# PIC32MK1024MCF064 register map
Vendor: Microchip
Registers are 32-bit, read-write, reset 0x0 unless marked. A register's access mark holds for its fields unless they carry their own. Addresses are absolute, and some are shared; only a register's first bit layout is shown; [hi:lo] are bit positions; {n}, {i} and the like mark numbered series.

## CFG
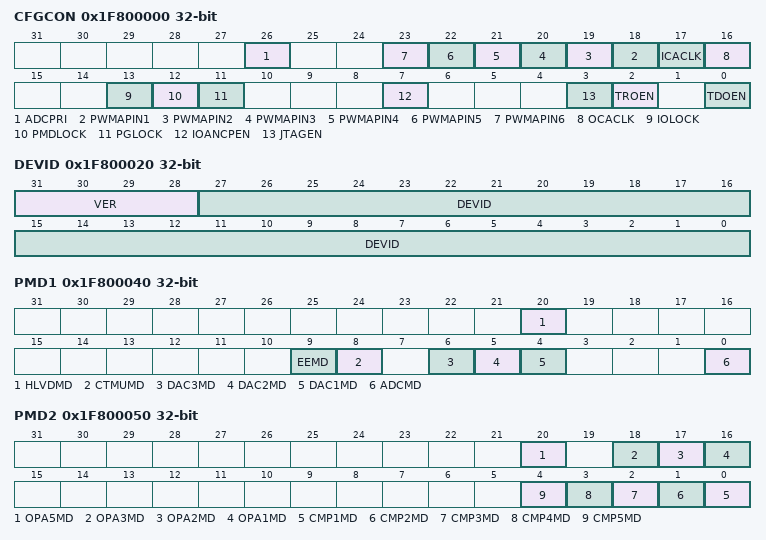
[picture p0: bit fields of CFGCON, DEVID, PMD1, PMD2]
0x1F800000 CFGCON reset not defined — (power-on value -----0--xxxxxx00--000---0---10-1)
  [26] ADCPRI, [n+17] PWMAPIN{n} (n=1..6), [17] ICACLK, [16] OCACLK, [13] IOLOCK, [12] PMDLOCK, [11] PGLOCK, [7] IOANCPEN, [3] JTAGEN, [2] TROEN, [0] TDOEN
0x1F800020 DEVID reset not defined — (power-on value 0000xxxxxxxxxxxxxxxxxxxxxxxxxxxx)
  [31:28] VER ro, [27:0] DEVID
0x1F800030 SYSKEY
0x1F800040 PMD1 reset not defined — (power-on value -----------x---------xxx-xxx---0)
  [20] HLVDMD, [9] EEMD, [8] CTMUMD, [6] DAC3MD, [5] DAC2MD, [4] DAC1MD, [0] ADCMD
0x1F800050 PMD2 reset not defined — (power-on value -----------x-xxx-----------xxx00)
  [20] OPA5MD, [18] OPA3MD, [17] OPA2MD, [16] OPA1MD, [n-1] CMP{n}MD (n=1..5)
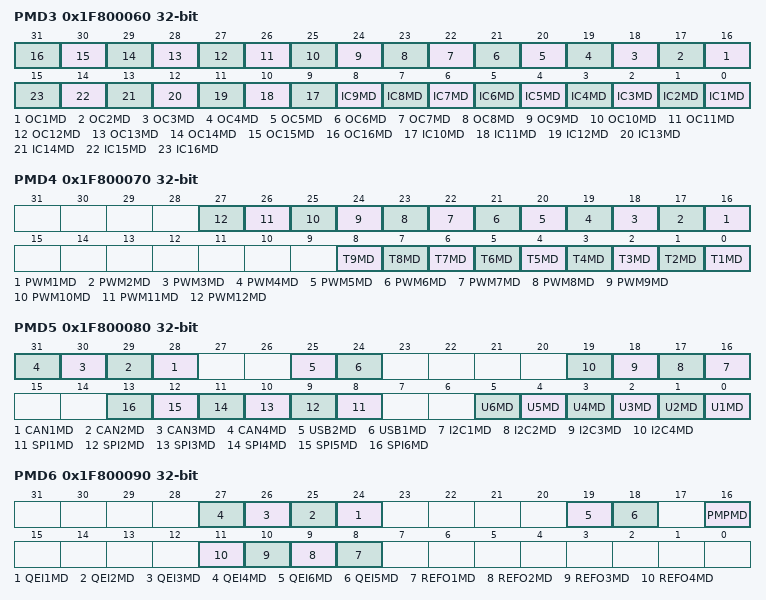
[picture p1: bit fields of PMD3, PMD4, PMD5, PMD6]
0x1F800060 PMD3 reset not defined — (power-on value xxxxxxx000000000xxxxxxx000000000)
  [n+15] OC{n}MD (n=1..16), [n-1] IC{n}MD (n=1..16)
0x1F800070 PMD4 reset not defined — (power-on value ----xxxxxxxxxxxx-------111111111)
  [n+15] PWM{n}MD (n=1..12), [n-1] T{n}MD (n=1..9)
0x1F800080 PMD5 reset not defined — (power-on value xx00--x0----0000--000000--000000)
  [n+27] CAN{n}MD (n=1..4), [25] USB2MD, [24] USB1MD, [n+15] I2C{n}MD (n=1..4), [n+7] SPI{n}MD (n=1..6), [n-1] U{n}MD (n=1..6)
0x1F800090 PMD6 reset not defined — (power-on value ----xxxx----xxx0----0000--------)
  [n+23] QEI{n}MD (n=1..4), [19] QEI6MD, [18] QEI5MD, [16] PMPMD, [n+7] REFO{n}MD (n=1..4)
0x1F8000A0 PMD7
  [4] DMAMD
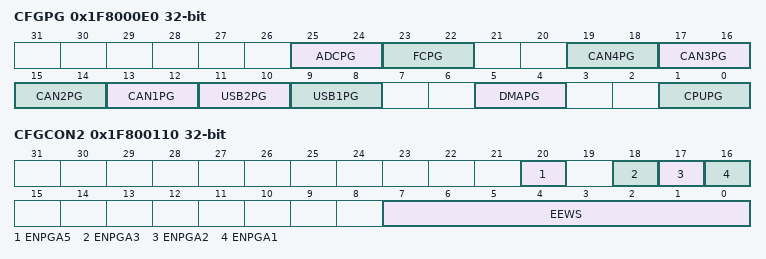
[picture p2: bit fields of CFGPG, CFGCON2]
0x1F8000E0 CFGPG reset not defined — (power-on value ------0000--00000000xx00--00--00)
  [25:24] ADCPG, [23:22] FCPG, [2n+11:2n+10] CAN{n}PG (n=1..4), [11:10] USB2PG, [9:8] USB1PG, [5:4] DMAPG, [1:0] CPUPG
0x1F800110 CFGCON2 reset not defined — (power-on value -----------x-xxx--------00000000)
  [20] ENPGA5, [18] ENPGA3, [17] ENPGA2, [16] ENPGA1, [7:0] EEWS

## PCACHE
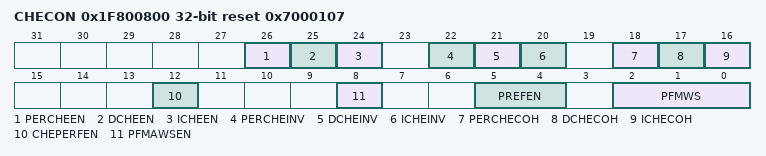
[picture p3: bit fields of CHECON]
0x1F800800 CHECON reset 0x7000107
  [26] PERCHEEN, [25] DCHEEN, [24] ICHEEN, [22] PERCHEINV, [21] DCHEINV, [20] ICHEINV, [18] PERCHECOH, [17] DCHECOH, [16] ICHECOH, [12] CHEPERFEN, [8] PFMAWSEN, [5:4] PREFEN, [2:0] PFMWS
0x1F800820 CHEHIT reset not defined — (power-on value xxxxxxxxxxxxxxxxxxxxxxxxxxxxxxxx)
  [31:0] CHEHIT — (can only be cleared)
0x1F800830 CHEMIS reset not defined — (power-on value xxxxxxxxxxxxxxxxxxxxxxxxxxxxxxxx)
  [31:0] CHEMIS — (can only be cleared)

## NVM
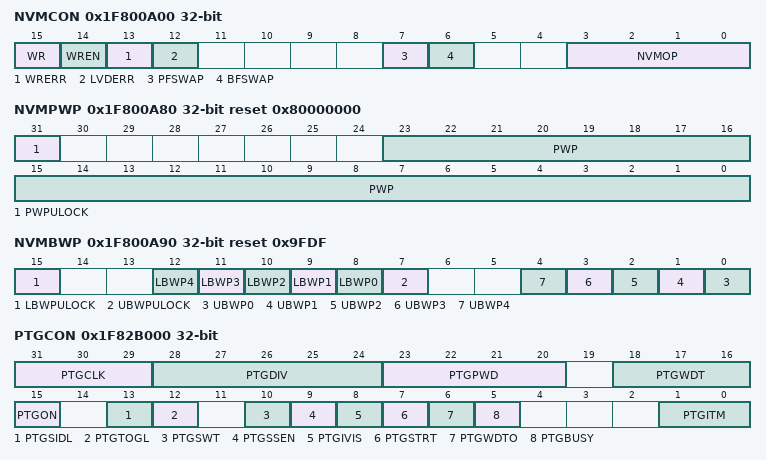
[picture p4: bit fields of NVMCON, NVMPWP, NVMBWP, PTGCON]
0x1F800A00 NVMCON reset not defined — (power-on value ----------------0000----0x--0000)
  [15] WR, [14] WREN, [13] WRERR, [12] LVDERR, [7] PFSWAP, [6] BFSWAP, [3:0] NVMOP
0x1F800A10 NVMKEY wo
0x1F800A20 NVMADDR
{0x1F800A30+0x10*i} NVMDATA{i} (i=0..3)
0x1F800A70 NVMSRCADDR
0x1F800A80 NVMPWP reset 0x80000000
  [31] PWPULOCK, [23:0] PWP
0x1F800A90 NVMBWP reset 0x9FDF
  [15] LBWPULOCK, [n+8] LBWP{n} (n=0..4), [7] UBWPULOCK, [n] UBWP{n} (n=0..4)
0x1F800AA0 NVMCON2 reset not defined — (power-on value xxxx-------xxxxxx-xx--xx00------)
  [7:6] SWAPLOCK
0x1F82B000 PTGCON
  [31:29] PTGCLK, [28:24] PTGDIV, [23:20] PTGPWD, [18:16] PTGWDT, [15] PTGON, [13] PTGSIDL, [12] PTGTOGL, [10] PTGSWT, [9] PTGSSEN, [8] PTGIVIS, [7] PTGSTRT, [6] PTGWDTO ro, [5] PTGBUSY ro, [1:0] PTGITM
0x1F82B010 PTGBTE
0x1F82B020 PTGHOLD
  [15:0] PTGHOLD
0x1F82B030 PTGT0LIM
  [15:0] PTGT0LIM
0x1F82B040 PTGT1LIM
  [15:0] PTGT1LIM
0x1F82B050 PTGSDLIM
  [15:0] PTGSDLIM
0x1F82B060 PTGC0LIM
  [15:0] PTGC0LIM
0x1F82B070 PTGC1LIM
  [15:0] PTGC1LIM
0x1F82B080 PTGADJ
  [15:0] PTGADJ
0x1F82B090 PTGL0
  [15:0] PTGL0
0x1F82B0A0 PTGQPTR
  [4:0] PTGQPTR
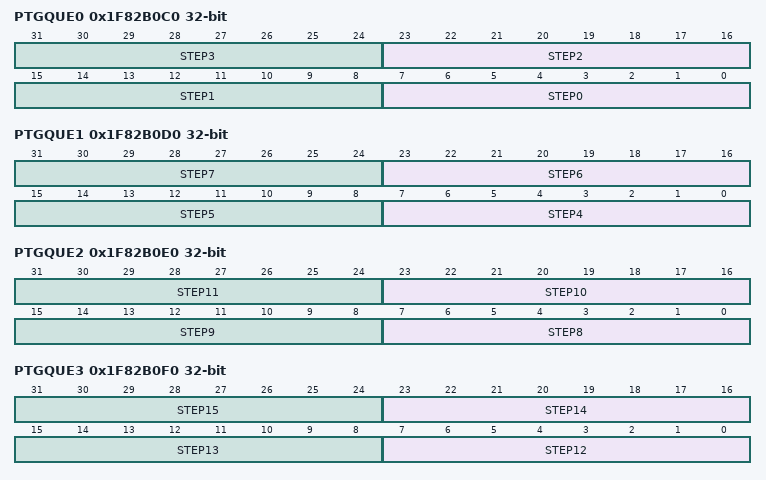
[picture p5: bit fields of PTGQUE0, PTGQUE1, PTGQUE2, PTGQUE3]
0x1F82B0C0 PTGQUE0
  [8n+7:8n] STEP{n} (n=0..3)
0x1F82B0D0 PTGQUE1
  [8n-25:8n-32] STEP{n} (n=4..7)
0x1F82B0E0 PTGQUE2
  [8n-57:8n-64] STEP{n} (n=8..11)
0x1F82B0F0 PTGQUE3
  [8n-89:8n-96] STEP{n} (n=12..15)
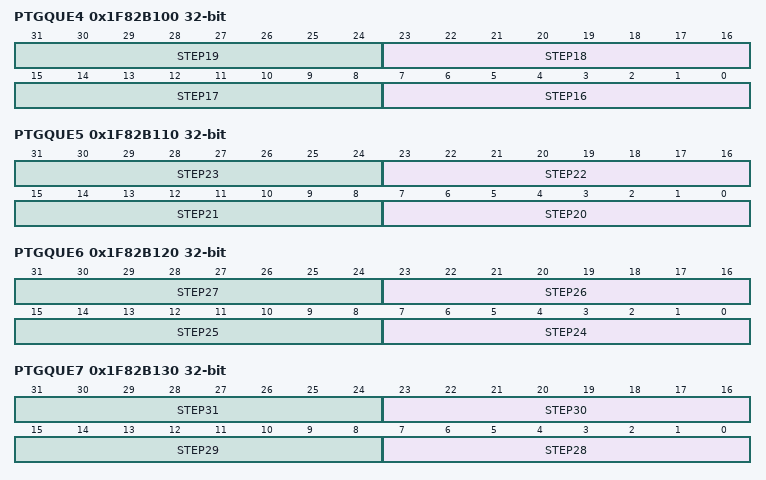
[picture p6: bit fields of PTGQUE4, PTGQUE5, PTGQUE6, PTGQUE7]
0x1F82B100 PTGQUE4
  [8n-121:8n-128] STEP{n} (n=16..19)
0x1F82B110 PTGQUE5
  [8n-153:8n-160] STEP{n} (n=20..23)
0x1F82B120 PTGQUE6
  [8n-185:8n-192] STEP{n} (n=24..27)
0x1F82B130 PTGQUE7
  [8n-217:8n-224] STEP{n} (n=28..31)
